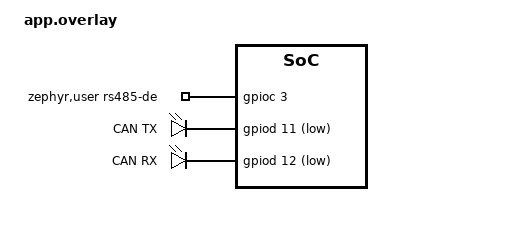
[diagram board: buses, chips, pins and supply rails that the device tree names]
/ {
	zephyr,user {
		rs485-de-gpios = <&gpioc 3 GPIO_ACTIVE_HIGH>;
	};
};
/ {
	can_leds {
		compatible = "gpio-leds";
		can_tx_led: can_tx_led { gpios = <&gpiod 11 GPIO_ACTIVE_LOW>; label = "CAN TX"; };
		can_rx_led: can_rx_led { gpios = <&gpiod 12 GPIO_ACTIVE_LOW>; label = "CAN RX"; };
	};
};
